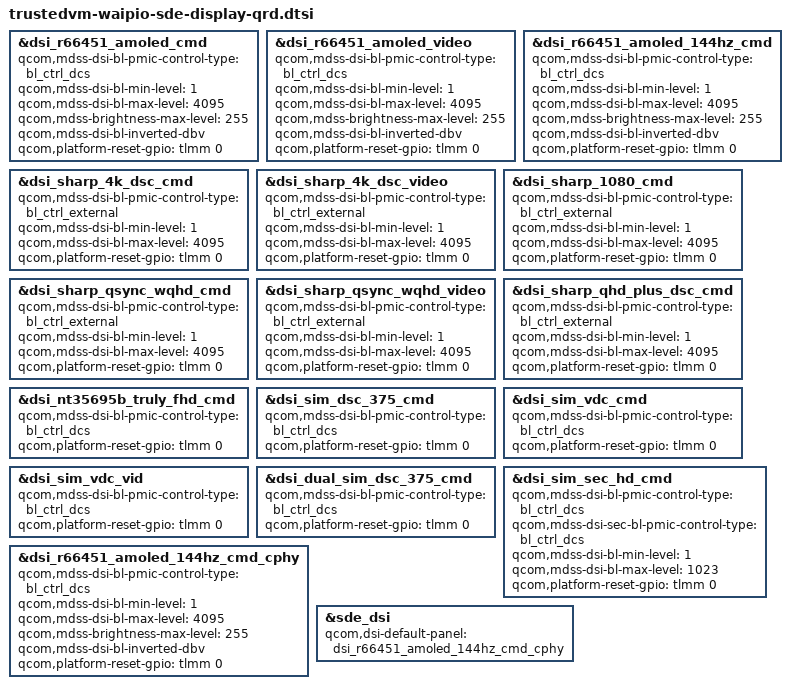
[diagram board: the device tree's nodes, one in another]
#include "trustedvm-waipio-sde-display.dtsi"

&dsi_r66451_amoled_cmd {
	qcom,mdss-dsi-bl-pmic-control-type = "bl_ctrl_dcs";
	qcom,mdss-dsi-bl-min-level = <1>;
	qcom,mdss-dsi-bl-max-level = <4095>;
	qcom,mdss-brightness-max-level = <255>;
	qcom,mdss-dsi-bl-inverted-dbv;
	qcom,platform-reset-gpio = <&tlmm 0 0>;
};

&dsi_r66451_amoled_video {
	qcom,mdss-dsi-bl-pmic-control-type = "bl_ctrl_dcs";
	qcom,mdss-dsi-bl-min-level = <1>;
	qcom,mdss-dsi-bl-max-level = <4095>;
	qcom,mdss-brightness-max-level = <255>;
	qcom,mdss-dsi-bl-inverted-dbv;
	qcom,platform-reset-gpio = <&tlmm 0 0>;
};

&dsi_r66451_amoled_144hz_cmd {
	qcom,mdss-dsi-bl-pmic-control-type = "bl_ctrl_dcs";
	qcom,mdss-dsi-bl-min-level = <1>;
	qcom,mdss-dsi-bl-max-level = <4095>;
	qcom,mdss-brightness-max-level = <255>;
	qcom,mdss-dsi-bl-inverted-dbv;
	qcom,platform-reset-gpio = <&tlmm 0 0>;
};

&dsi_sharp_4k_dsc_cmd {
	qcom,mdss-dsi-bl-pmic-control-type = "bl_ctrl_external";
	qcom,mdss-dsi-bl-min-level = <1>;
	qcom,mdss-dsi-bl-max-level = <4095>;
	qcom,platform-reset-gpio = <&tlmm 0 0>;
};

&dsi_sharp_4k_dsc_video {
	qcom,mdss-dsi-bl-pmic-control-type = "bl_ctrl_external";
	qcom,mdss-dsi-bl-min-level = <1>;
	qcom,mdss-dsi-bl-max-level = <4095>;
	qcom,platform-reset-gpio = <&tlmm 0 0>;
};

&dsi_sharp_1080_cmd {
	qcom,mdss-dsi-bl-pmic-control-type = "bl_ctrl_external";
	qcom,mdss-dsi-bl-min-level = <1>;
	qcom,mdss-dsi-bl-max-level = <4095>;
	qcom,platform-reset-gpio = <&tlmm 0 0>;
};

&dsi_sharp_qsync_wqhd_cmd {
	qcom,mdss-dsi-bl-pmic-control-type = "bl_ctrl_external";
	qcom,mdss-dsi-bl-min-level = <1>;
	qcom,mdss-dsi-bl-max-level = <4095>;
	qcom,platform-reset-gpio = <&tlmm 0 0>;
};

&dsi_sharp_qsync_wqhd_video {
	qcom,mdss-dsi-bl-pmic-control-type = "bl_ctrl_external";
	qcom,mdss-dsi-bl-min-level = <1>;
	qcom,mdss-dsi-bl-max-level = <4095>;
	qcom,platform-reset-gpio = <&tlmm 0 0>;
};

&dsi_sharp_qhd_plus_dsc_cmd {
	qcom,mdss-dsi-bl-pmic-control-type = "bl_ctrl_external";
	qcom,mdss-dsi-bl-min-level = <1>;
	qcom,mdss-dsi-bl-max-level = <4095>;
	qcom,platform-reset-gpio = <&tlmm 0 0>;
};

&dsi_nt35695b_truly_fhd_cmd {
	qcom,mdss-dsi-bl-pmic-control-type = "bl_ctrl_dcs";
	qcom,platform-reset-gpio = <&tlmm 0 0>;
};

&dsi_sim_dsc_375_cmd {
	qcom,mdss-dsi-bl-pmic-control-type = "bl_ctrl_dcs";
	qcom,platform-reset-gpio = <&tlmm 0 0>;
};

&dsi_sim_vdc_cmd {
	qcom,mdss-dsi-bl-pmic-control-type = "bl_ctrl_dcs";
	qcom,platform-reset-gpio = <&tlmm 0 0>;
};

&dsi_sim_vdc_vid {
	qcom,mdss-dsi-bl-pmic-control-type = "bl_ctrl_dcs";
	qcom,platform-reset-gpio = <&tlmm 0 0>;
};

&dsi_dual_sim_dsc_375_cmd {
	qcom,mdss-dsi-bl-pmic-control-type = "bl_ctrl_dcs";
	qcom,platform-reset-gpio = <&tlmm 0 0>;
};

&dsi_sim_sec_hd_cmd {
	qcom,mdss-dsi-bl-pmic-control-type = "bl_ctrl_dcs";
	qcom,mdss-dsi-sec-bl-pmic-control-type = "bl_ctrl_dcs";
	qcom,mdss-dsi-bl-min-level = <1>;
	qcom,mdss-dsi-bl-max-level = <1023>;
	qcom,platform-reset-gpio = <&tlmm 0 0>;
};

&dsi_r66451_amoled_144hz_cmd_cphy {
	qcom,mdss-dsi-bl-pmic-control-type = "bl_ctrl_dcs";
	qcom,mdss-dsi-bl-min-level = <1>;
	qcom,mdss-dsi-bl-max-level = <4095>;
	qcom,mdss-brightness-max-level = <255>;
	qcom,mdss-dsi-bl-inverted-dbv;
	qcom,platform-reset-gpio = <&tlmm 0 0>;
};

&sde_dsi {
	qcom,dsi-default-panel = <&dsi_r66451_amoled_144hz_cmd_cphy>;
};
